VERSION ""

NS_ :

BS_:

BU_: ECU

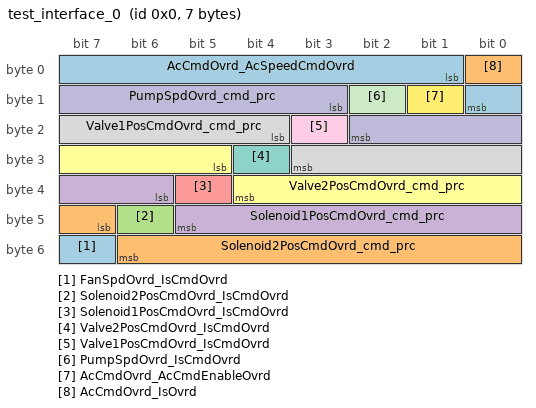
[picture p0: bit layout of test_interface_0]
BO_ 0 test_interface_0: 7 ECU
 SG_ FanSpdOvrd_IsCmdOvrd : 55|1@1+ (1,0) [0|1.0] ""  ECU
 SG_ Solenoid2PosCmdOvrd_cmd_prc : 47|8@1+ (0.1,0) [0|100.0] ""  ECU
 SG_ Solenoid2PosCmdOvrd_IsCmdOvrd : 46|1@1+ (1,0) [0|1.0] ""  ECU
 SG_ Solenoid1PosCmdOvrd_cmd_prc : 38|8@1+ (0.1,0) [0|100.0] ""  ECU
 SG_ Solenoid1PosCmdOvrd_IsCmdOvrd : 37|1@1+ (1,0) [0|1.0] ""  ECU
 SG_ Valve2PosCmdOvrd_cmd_prc : 29|8@1+ (0.1,0) [0|100.0] ""  ECU
 SG_ Valve2PosCmdOvrd_IsCmdOvrd : 28|1@1+ (1,0) [0|1.0] ""  ECU
 SG_ Valve1PosCmdOvrd_cmd_prc : 20|8@1+ (0.1,0) [0|100.0] ""  ECU
 SG_ Valve1PosCmdOvrd_IsCmdOvrd : 19|1@1+ (1,0) [0|1.0] ""  ECU
 SG_ PumpSpdOvrd_cmd_prc : 11|8@1+ (0.1,0) [0|100.0] ""  ECU
 SG_ PumpSpdOvrd_IsCmdOvrd : 10|1@1+ (1,0) [0|1.0] ""  ECU
 SG_ AcCmdOvrd_AcCmdEnableOvrd : 9|1@1+ (1,0) [0|1.0] ""  ECU
 SG_ AcCmdOvrd_AcSpeedCmdOvrd : 1|8@1+ (1,0) [0|65535.0] ""  ECU
 SG_ AcCmdOvrd_IsOvrd : 0|1@1+ (1,0) [0|1.0] ""  ECU

BO_ 1 test_interface_1: 1 ECU
 SG_ FanSpdOvrd_cmd_prc : 0|8@1+ (0.1,0) [0|100.0] ""  ECU

BA_DEF_ BO_  "GenMsgCycleTime" INT 0 65535;
BA_DEF_DEF_  "GenMsgCycleTime" 0;
BA_ "GenMsgCycleTime" BO_ 0 100;
BA_ "GenMsgCycleTime" BO_ 1 100;
